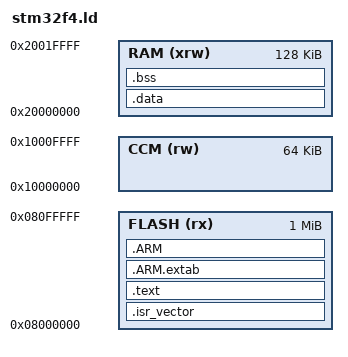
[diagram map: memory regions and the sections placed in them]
/*
Copyright (c) 2014, Martin Åberg All rights reserved.

Redistribution and use in source and binary forms, with or without
modification, are permitted provided that the following conditions are met:

1. Redistributions of source code must retain the above copyright notice,
   this list of conditions and the following disclaimer.
2. Redistributions in binary form must reproduce the above copyright notice,
   this list of conditions and the following disclaimer in the documentation
   and/or other materials provided with the distribution.
3. The names of the copyright holder(s) may not be used to endorse or
   promote products derived from this software without specific prior
   written permission.

THIS SOFTWARE IS PROVIDED BY THE COPYRIGHT HOLDERS AND CONTRIBUTORS "AS IS"
AND ANY EXPRESS OR IMPLIED WARRANTIES, INCLUDING, BUT NOT LIMITED TO, THE
IMPLIED WARRANTIES OF MERCHANTABILITY AND FITNESS FOR A PARTICULAR PURPOSE ARE
DISCLAIMED. IN NO EVENT SHALL THE COPYRIGHT HOLDER OR CONTRIBUTORS BE LIABLE
FOR ANY DIRECT, INDIRECT, INCIDENTAL, SPECIAL, EXEMPLARY, OR CONSEQUENTIAL
DAMAGES (INCLUDING, BUT NOT LIMITED TO, PROCUREMENT OF SUBSTITUTE GOODS OR
SERVICES; LOSS OF USE, DATA, OR PROFITS; OR BUSINESS INTERRUPTION) HOWEVER
CAUSED AND ON ANY THEORY OF LIABILITY, WHETHER IN CONTRACT, STRICT LIABILITY,
OR TORT (INCLUDING NEGLIGENCE OR OTHERWISE) ARISING IN ANY WAY OUT OF THE
USE OF THIS SOFTWARE, EVEN IF ADVISED OF THE POSSIBILITY OF SUCH DAMAGE.
*/

/* This is a linker script for the STM32F4. */

/* Entry Point */
ENTRY(Reset_Handler)

/* Highest address of the user mode stack */
_tos = 0x20020000;    /* end of 128K RAM on AHB bus*/

/* Specify the memory areas */
MEMORY
{
  FLASH (rx)      : ORIGIN = 0x08000000, LENGTH = 1024K
  /* Core couple memory. Accessible from D-BUS. */
  CCM (rw)        : ORIGIN = 0x10000000, LENGTH = 64K
  /* Accessible from D-BUS, I-BUS and S-BUS.
  SRAM1: 112K, SRAM2: 16K */
  RAM (xrw)       : ORIGIN = 0x20000000, LENGTH = 128K
}

/* Define output sections */
SECTIONS
{
  /* The startup code goes first into FLASH. It must end up
  at address 0. */
  .isr_vector :
  {
    . = ALIGN(4);
    KEEP(*(.isr_vector)) /* Startup code */
    . = ALIGN(4);
  } >FLASH

  /* The program code and other data goes into FLASH */
  .text :
  {
    . = ALIGN(4);
    *(.text)           /* .text sections (code) */
    *(.text*)          /* .text* sections (code) */
    *(.rodata)         /* .rodata sections (constants, strings, etc.) */
    *(.rodata*)        /* .rodata* sections (constants, strings, etc.) */
    *(.glue_7)         /* glue arm to thumb code */
    *(.glue_7t)        /* glue thumb to arm code */
	*(.eh_frame)

    KEEP (*(.init))
    KEEP (*(.fini))

    . = ALIGN(4);
  } >FLASH

  .ARM.extab :
  {
    *(.ARM.extab* .gnu.linkonce.armextab.*)
  } >FLASH

  .ARM :
  {
    __exidx_start = .;
    *(.ARM.exidx*)
    __exidx_end = .;
  } >FLASH

  /* used by the startup to initialize data */
  _sidata = .;

  /* Initialized data sections goes into RAM, load LMA copy after code */
  .data : AT ( _sidata )
  {
    . = ALIGN(4);
    _sdata = .;        /* create a global symbol at data start */
    *(.data)           /* .data sections */
    *(.data*)          /* .data* sections */

    . = ALIGN(4);
    _edata = .;        /* define a global symbol at data end */
  } >RAM
  _data_size = _edata - _sdata;

  /* Uninitialized data section */
  . = ALIGN(4);
  .bss :
  {
    /* This is used by the startup in order to initialize the .bss secion */
    _sbss = .;         /* define a global symbol at bss start */
/*    __bss_start__ = _sbss; */
    *(.bss)
    *(.bss*)
    *(COMMON)

    . = ALIGN(4);
    _ebss = .;         /* define a global symbol at bss end */
/*    __bss_end__ = _ebss; */
  } >RAM
  _bss_size = _ebss - _sbss;

  /* Remove information from the standard libraries */
  /DISCARD/ :
  {
    libc.a ( * )
    libm.a ( * )
    libgcc.a ( * )
  }

  .ARM.attributes 0 :
  {
    *(.ARM.attributes)
  }
}

